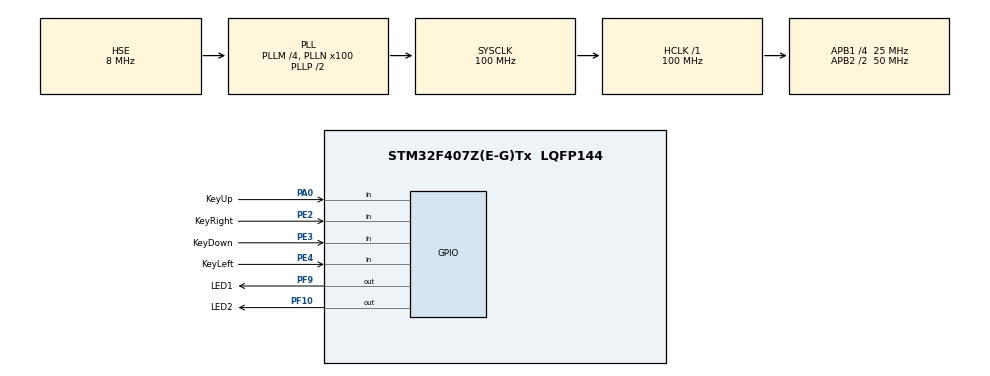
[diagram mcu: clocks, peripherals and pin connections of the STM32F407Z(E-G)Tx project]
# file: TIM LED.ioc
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Mcu.Family=STM32F4
Mcu.Name=STM32F407Z(E-G)Tx
Mcu.Package=LQFP144
NVIC.PriorityGroup=NVIC_PRIORITYGROUP_2
NVIC.TIM6_DAC_IRQn=true\:1\:0\:true\:false\:true\:true\:true\:true
NVIC.TIM7_IRQn=true\:1\:0\:true\:false\:true\:true\:true\:true
PA0-WKUP.GPIO_Label=KeyUp
PA0-WKUP.GPIO_PuPd=GPIO_PULLDOWN
PA0-WKUP.Signal=GPIO_Input
PA13.Mode=Serial_Wire
PA13.Signal=SYS_JTMS-SWDIO
PA14.Mode=Serial_Wire
PA14.Signal=SYS_JTCK-SWCLK
PD0.GPIO_PuPd=GPIO_NOPULL
PD0.Signal=FSMC_D2_DA2
PD1.GPIO_PuPd=GPIO_NOPULL
PD1.Signal=FSMC_D3_DA3
PD10.GPIO_PuPd=GPIO_NOPULL
PD10.Signal=FSMC_D15_DA15
PD14.GPIO_PuPd=GPIO_NOPULL
PD14.Signal=FSMC_D0_DA0
PD15.GPIO_PuPd=GPIO_NOPULL
PD15.Signal=FSMC_D1_DA1
PD4.GPIO_PuPd=GPIO_NOPULL
PD4.Signal=FSMC_NOE
PD5.GPIO_PuPd=GPIO_NOPULL
PD5.Signal=FSMC_NWE
PD8.GPIO_PuPd=GPIO_NOPULL
PD8.Signal=FSMC_D13_DA13
PD9.GPIO_PuPd=GPIO_NOPULL
PD9.Signal=FSMC_D14_DA14
PE10.GPIO_PuPd=GPIO_NOPULL
PE10.Signal=FSMC_D7_DA7
PE11.GPIO_PuPd=GPIO_NOPULL
PE11.Signal=FSMC_D8_DA8
PE12.GPIO_PuPd=GPIO_NOPULL
PE12.Signal=FSMC_D9_DA9
PE13.GPIO_PuPd=GPIO_NOPULL
PE13.Signal=FSMC_D10_DA10
PE14.GPIO_PuPd=GPIO_NOPULL
PE14.Signal=FSMC_D11_DA11
PE15.GPIO_PuPd=GPIO_NOPULL
PE15.Signal=FSMC_D12_DA12
PE2.GPIO_Label=KeyRight
PE2.GPIO_PuPd=GPIO_PULLUP
PE2.Signal=GPIO_Input
PE3.GPIO_Label=KeyDown
PE3.GPIO_PuPd=GPIO_PULLUP
PE3.Signal=GPIO_Input
PE4.GPIO_Label=KeyLeft
PE4.GPIO_PuPd=GPIO_PULLUP
PE4.Signal=GPIO_Input
PE7.GPIO_PuPd=GPIO_NOPULL
PE7.Signal=FSMC_D4_DA4
PE8.GPIO_PuPd=GPIO_NOPULL
PE8.Signal=FSMC_D5_DA5
PE9.GPIO_PuPd=GPIO_NOPULL
PE9.Signal=FSMC_D6_DA6
PF10.GPIO_Label=LED2
PF10.GPIO_Speed=GPIO_SPEED_FREQ_LOW
PF10.Signal=GPIO_Output
PF12.GPIO_PuPd=GPIO_NOPULL
PF12.Signal=FSMC_A6
PF9.GPIO_Label=LED1
PF9.GPIO_Speed=GPIO_SPEED_FREQ_LOW
PF9.Signal=GPIO_Output
PG12.GPIO_PuPd=GPIO_NOPULL
PG12.Signal=FSMC_NE4
PH0-OSC_IN.Mode=HSE-External-Oscillator
PH0-OSC_IN.Signal=RCC_OSC_IN
PH1-OSC_OUT.Mode=HSE-External-Oscillator
PH1-OSC_OUT.Signal=RCC_OSC_OUT
ProjectManager.HeapSize=0x200
ProjectManager.StackSize=0x400
ProjectManager.TargetToolchain=MDK-ARM V5.32
RCC.48MHZClocksFreq_Value=50000000
RCC.AHBFreq_Value=100000000
RCC.APB1CLKDivider=RCC_HCLK_DIV4
RCC.APB1Freq_Value=25000000
RCC.APB1TimFreq_Value=50000000
RCC.APB2CLKDivider=RCC_HCLK_DIV2
RCC.APB2Freq_Value=50000000
RCC.APB2TimFreq_Value=100000000
RCC.CortexFreq_Value=100000000
RCC.FLatency=FLASH_LATENCY_3
RCC.HCLKFreq_Value=100000000
RCC.HSE_VALUE=8000000
RCC.HSI_VALUE=16000000
RCC.LSE_VALUE=32768
RCC.PLLM=4
RCC.PLLN=100
RCC.PLLSourceVirtual=RCC_PLLSOURCE_HSE
RCC.SYSCLKFreq_VALUE=100000000
RCC.SYSCLKSource=RCC_SYSCLKSOURCE_PLLCLK
RCC.VCOOutputFreq_Value=200000000
SH.FSMC_A6.0=FSMC_A6
SH.FSMC_D0_DA0.0=FSMC_D0
SH.FSMC_D10_DA10.0=FSMC_D10
SH.FSMC_D11_DA11.0=FSMC_D11
SH.FSMC_D12_DA12.0=FSMC_D12
SH.FSMC_D13_DA13.0=FSMC_D13
SH.FSMC_D14_DA14.0=FSMC_D14
SH.FSMC_D15_DA15.0=FSMC_D15
SH.FSMC_D1_DA1.0=FSMC_D1
SH.FSMC_D2_DA2.0=FSMC_D2
SH.FSMC_D3_DA3.0=FSMC_D3
SH.FSMC_D4_DA4.0=FSMC_D4
SH.FSMC_D5_DA5.0=FSMC_D5
SH.FSMC_D6_DA6.0=FSMC_D6
SH.FSMC_D7_DA7.0=FSMC_D7
SH.FSMC_D8_DA8.0=FSMC_D8
SH.FSMC_D9_DA9.0=FSMC_D9
SH.FSMC_NOE.0=FSMC_NOE
SH.FSMC_NWE.0=FSMC_NWE
TIM6.AutoReloadPreload=TIM_AUTORELOAD_PRELOAD_DISABLE
TIM6.CounterMode=TIM_COUNTERMODE_UP
TIM6.Period=500
TIM6.Prescaler=49999
TIM6.TIM_MasterOutputTrigger=TIM_TRGO_RESET
TIM7.AutoReloadPreload=TIM_AUTORELOAD_PRELOAD_DISABLE
TIM7.CounterMode=TIM_COUNTERMODE_UP
TIM7.Period=2000
TIM7.Prescaler=49999
TIM7.TIM_MasterOutputTrigger=TIM_TRGO_RESET
VP_TIM6_VS_ClockSourceINT.Mode=Enable_Timer
VP_TIM7_VS_ClockSourceINT.Mode=Enable_Timer
VP_TIM7_VS_OPM.Mode=OPM_bit
board=custom

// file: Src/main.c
/* USER CODE BEGIN Header */
/**
  ******************************************************************************
  * @file           : main.c
  * @brief          : Main program body
  ******************************************************************************
  * @attention
  *
  * Copyright (c) 2022 STMicroelectronics.
  * All rights reserved.
  *
  * This software is licensed under terms that can be found in the LICENSE file
  * in the root directory of this software component.
  * If no LICENSE file comes with this software, it is provided AS-IS.
  *
  ******************************************************************************
  */
/* USER CODE END Header */
#include "main.h"
#include "tim.h"
#include "gpio.h"

/* USER CODE BEGIN Includes */
#include "KEY_LED.h"
/* USER CODE END Includes */

void SystemClock_Config(void);

int main(void)
{

  /* MCU Configuration--------------------------------------------------------*/

  /* Reset of all peripherals, Initializes the Flash interface and the Systick. */
  HAL_Init();

  /* Configure the system clock */
  SystemClock_Config();

  /* Initialize all configured peripherals */
  MX_GPIO_Init();
  MX_TIM6_Init();
  MX_TIM7_Init();
  /* USER CODE BEGIN 2 */
  LED1_OFF();
  LED2_OFF();
  HAL_TIM_Base_Start_IT(&htim6);
  /* USER CODE END 2 */

  /* Infinite loop */
  while (1)
  {

    /* USER CODE BEGIN 3 */
	  	KEYS  curKey=ScanPressdKey(KEY_WAIT_ALWAYS);
		if (curKey==KEY_RIGHT)
		{

			HAL_TIM_Base_Start_IT(&htim7); 	//???????TIM7
			HAL_Delay(300);			//??????????
			LED2_ON();		//??LED2
		}
  }
  /* USER CODE END 3 */
}

void SystemClock_Config(void)
{
  RCC_OscInitTypeDef RCC_OscInitStruct = {0};
  RCC_ClkInitTypeDef RCC_ClkInitStruct = {0};

  /** Configure the main internal regulator output voltage
  */
  __HAL_RCC_PWR_CLK_ENABLE();
  __HAL_PWR_VOLTAGESCALING_CONFIG(PWR_REGULATOR_VOLTAGE_SCALE1);

  /** Initializes the RCC Oscillators according to the specified parameters
  * in the RCC_OscInitTypeDef structure.
  */
  RCC_OscInitStruct.OscillatorType = RCC_OSCILLATORTYPE_HSE;
  RCC_OscInitStruct.HSEState = RCC_HSE_ON;
  RCC_OscInitStruct.PLL.PLLState = RCC_PLL_ON;
  RCC_OscInitStruct.PLL.PLLSource = RCC_PLLSOURCE_HSE;
  RCC_OscInitStruct.PLL.PLLM = 4;
  RCC_OscInitStruct.PLL.PLLN = 100;
  RCC_OscInitStruct.PLL.PLLP = RCC_PLLP_DIV2;
  RCC_OscInitStruct.PLL.PLLQ = 4;
  if (HAL_RCC_OscConfig(&RCC_OscInitStruct) != HAL_OK)
  {
    Error_Handler();
  }

  /** Initializes the CPU, AHB and APB buses clocks
  */
  RCC_ClkInitStruct.ClockType = RCC_CLOCKTYPE_HCLK|RCC_CLOCKTYPE_SYSCLK
                              |RCC_CLOCKTYPE_PCLK1|RCC_CLOCKTYPE_PCLK2;
  RCC_ClkInitStruct.SYSCLKSource = RCC_SYSCLKSOURCE_PLLCLK;
  RCC_ClkInitStruct.AHBCLKDivider = RCC_SYSCLK_DIV1;
  RCC_ClkInitStruct.APB1CLKDivider = RCC_HCLK_DIV4;
  RCC_ClkInitStruct.APB2CLKDivider = RCC_HCLK_DIV2;

  if (HAL_RCC_ClockConfig(&RCC_ClkInitStruct, FLASH_LATENCY_3) != HAL_OK)
  {
    Error_Handler();
  }
}

void Error_Handler(void)
{
  __disable_irq();
  while (1)
  {
  }
}
